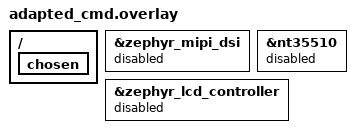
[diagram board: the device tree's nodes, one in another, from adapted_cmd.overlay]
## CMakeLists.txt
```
# SPDX-License-Identifier: MIT
# Zephyr application for STM32H747I-DISCO rlvgl demo.
#
# Build:
#   west build -b stm32h747i_disco/stm32h747xx/m7 \
#       examples/stm32h747i-disco/zephyr \
#       -- -DSHIELD=st_b_lcd40_dsi1_mb1166_a09
#
# The Rust static library is built separately and linked via
# target_link_libraries. See README for the two-step build flow.

cmake_minimum_required(VERSION 3.20.0)
find_package(Zephyr REQUIRED HINTS $ENV{ZEPHYR_BASE})
project(rlvgl_disco_zephyr C)

target_sources(app PRIVATE src/main.c)

# Link the Rust static library built by cargo.
# The library path assumes cargo was invoked from the workspace root:
#   RUSTFLAGS="-C target-cpu=cortex-m7" cargo build \
#       --target thumbv7em-none-eabihf \
#       -p rlvgl-example-disco \
#       --features cm7,dma2d,splash,desktop,zephyr \
#       --lib
#
# Adjust the path if your build layout differs.
set(RLVGL_RUST_LIB
    ${CMAKE_CURRENT_SOURCE_DIR}/../../../target/thumbv7em-none-eabihf/debug/librlvgl_example_disco.a)

if(EXISTS ${RLVGL_RUST_LIB})
    target_link_libraries(app PUBLIC ${RLVGL_RUST_LIB})
else()
    message(WARNING "Rust library not found at ${RLVGL_RUST_LIB} — build the Rust side first.")
endif()
```

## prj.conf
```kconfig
# rlvgl STM32H747I-DISCO Zephyr demo
# Kernel
# 16 KiB main stack: render loop hosts the controller widget tree, the
# StarCrawl struct (~800 B scanline buffer), `RotatedRenderer`, and
# per-pixel `BlitterRenderer.draw_pixels` recursion. Default 4 KiB
# overflowed during crawl render and reset the board.
CONFIG_MAIN_STACK_SIZE=16384
CONFIG_FPU=y
CONFIG_SYSTEM_WORKQUEUE_STACK_SIZE=2048
CONFIG_HEAP_MEM_POOL_SIZE=65536

# Display subsystem
CONFIG_DISPLAY=y
CONFIG_STM32_LTDC_FB_NUM=2

# MIPI-DSI — Zephyr video-mode driver for initial bringup
CONFIG_MIPI_DSI=y

# I2C for FT5336 touch
CONFIG_I2C=y
CONFIG_INPUT=y
CONFIG_INPUT_FT5336=y
CONFIG_INPUT_FT5336_INTERRUPT=n
CONFIG_INPUT_FT5336_PERIOD=10

# Synchronous mode: input_report dispatches to callbacks inline,
# no msgq / thread. Avoids "queue full, event dropped" when main
# thread's render loop starves the input dispatch thread.
CONFIG_INPUT_MODE_SYNCHRONOUS=y

# SDRAM via FMC
CONFIG_MEMC=y
CONFIG_MEMC_STM32=y

# DMA2D (no Zephyr driver — raw register access from Rust)
# Enable the clock gate via DT overlay.

# Serial console
CONFIG_SERIAL=y
CONFIG_UART_INTERRUPT_DRIVEN=y
CONFIG_CONSOLE=y
CONFIG_UART_CONSOLE=y

# Logging — DBG on INPUT so FT5336 polling path prints its per-touch lines.
CONFIG_LOG=y
CONFIG_LOG_MODE_IMMEDIATE=y
CONFIG_LOG_DEFAULT_LEVEL=3
CONFIG_INPUT_LOG_LEVEL_DBG=y

# SD card via SDMMC
CONFIG_DISK_ACCESS=y
CONFIG_SDMMC_STM32=y

# QSPI flash
CONFIG_FLASH=y
CONFIG_FLASH_STM32_QSPI=y

# Filesystem: FatFS with multi-volume support
CONFIG_FILE_SYSTEM=y
CONFIG_FAT_FILESYSTEM_ELM=y
CONFIG_FS_FATFS_MAX_SS=512
CONFIG_FS_FATFS_LFN=y

# GPIO for scope probes, backlight, and joystick
CONFIG_GPIO=y
CONFIG_INPUT_GPIO_KEYS=y

# Interrupts
CONFIG_DYNAMIC_INTERRUPTS=y
```

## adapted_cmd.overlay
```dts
/*
 * Adapted command mode overlay — disables Zephyr's DSI/LTDC/NT35510
 * driver init so the Rust code can do full DSI+LTDC init from scratch
 * in adapted command mode.
 *
 * Apply via west: -DEXTRA_DTC_OVERLAY_FILE=adapted_cmd.overlay
 *
 * Zephyr keeps providing: SDRAM (memc), clocks (PLL3), GPIO, I2C,
 *   joystick (gpio_keys), kernel, filesystem, console.
 */

&zephyr_mipi_dsi {
	status = "disabled";
};

&nt35510 {
	status = "disabled";
};

&zephyr_lcd_controller {
	status = "disabled";
};

/ {
	chosen {
		/delete-property/ zephyr,display;
	};
};
```

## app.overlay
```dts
/*
 * Device tree overlay for rlvgl Zephyr demo on STM32H747I-DISCO.
 *
 * Uses the st_b_lcd40_dsi1_mb1166_a09 shield for NT35510 panel/touch
 * setup. This overlay disables the Zephyr DSI driver (video-mode only)
 * so that the Rust code can perform raw register adapted-command-mode
 * init instead.
 *
 * LTDC remains enabled — Zephyr's LTDC driver handles framebuffer in
 * SDRAM and the display API surface.
 */

/* Phase 5 bringup: let Zephyr's DSI driver init in video mode. */

/* Enable joystick buttons for navigation. */
&joy_center { status = "okay"; };
&joy_down   { status = "okay"; };
&joy_up     { status = "okay"; };
&joy_left   { status = "okay"; };
&joy_right  { status = "okay"; };
```

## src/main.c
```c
/*
 * SPDX-License-Identifier: MIT
 *
 * Zephyr C application shell for the rlvgl STM32H747I-DISCO demo.
 *
 * Defines kernel objects (semaphores, thread stacks) and ISR wrappers,
 * then calls into the Rust static library via rlvgl_init().
 */

#include <zephyr/kernel.h>
#include <zephyr/device.h>
#include <zephyr/irq.h>
#include <zephyr/drivers/display.h>
#include <zephyr/drivers/i2c.h>
#include <zephyr/drivers/gpio.h>
#include <zephyr/drivers/uart.h>
#include <zephyr/cache.h>
#include <zephyr/input/input.h>
#include <string.h>
#include <zephyr/fs/fs.h>
#include <ff.h>

/* ── Early PG3 reset pulse ──────────────────────────────────────────────
 *
 * On ACM builds the zephyr `nt35510` node is disabled by overlay, so
 * Zephyr never pulses the shared DSI/touch reset line (PG3). Meanwhile,
 * the FT5336 driver init runs at POST_KERNEL 50 and starts hammering the
 * chip with I2C reads immediately. The FT5336 IC apparently enters a
 * broken state when it receives I2C before its first reset — subsequent
 * resets recover it to "ACK but all-zero registers" rather than normal
 * operation.
 *
 * Fix: drop in a pre-POST_KERNEL SYS_INIT hook that pulses PG3 BEFORE
 * the FT5336 driver comes up, mimicking what Zephyr's NT35510 driver
 * would have done on a non-ACM build. Priority 45 runs ahead of the
 * default input-device priority of 50.
 */
static int ft5336_early_reset(void)
{
	const struct device *gpiog = DEVICE_DT_GET(DT_NODELABEL(gpiog));
	if (!device_is_ready(gpiog)) {
		return -ENODEV;
	}
	gpio_pin_configure(gpiog, 3, GPIO_OUTPUT_ACTIVE);
	gpio_pin_set(gpiog, 3, 0); /* low = hold in reset */
	k_busy_wait(10000);        /* 10 ms */
	gpio_pin_set(gpiog, 3, 1); /* high = release reset */
	k_busy_wait(300000);       /* 300 ms settle for chip boot */
	return 0;
}
SYS_INIT(ft5336_early_reset, POST_KERNEL, 45);

/* ── Kernel objects ──────────────────────────────────────────────────── */

K_SEM_DEFINE(erif_sem, 0, 1);
K_SEM_DEFINE(dma2d_done_sem, 0, 1);

/* ── Display info passed to Rust ─────────────────────────────────────── */

struct rlvgl_display_info {
	uint8_t *fb_front;       /* front framebuffer (currently displayed) */
	uint8_t *fb_back;        /* back framebuffer (render target) */
	uint32_t fb_len;         /* bytes per framebuffer */
	uint16_t width;          /* portrait width (480) */
	uint16_t height;         /* portrait height (800) */
	uint16_t pixel_size;     /* bytes per pixel (4 for ARGB8888) */
};

/* ── Rust FFI declarations ───────────────────────────────────────────── */

extern void rlvgl_init(struct k_sem *erif_sem,
		       struct k_sem *dma2d_done_sem,
		       const struct rlvgl_display_info *display_info);
extern void rlvgl_dsi_isr(void);
extern void rlvgl_dma2d_isr(void);

/* ── FFI wrappers for Zephyr kernel API ─────────────────────────────── */

int rlvgl_k_sem_take(struct k_sem *sem, k_timeout_t timeout)
{
	return k_sem_take(sem, timeout);
}

void rlvgl_k_sem_give(struct k_sem *sem)
{
	k_sem_give(sem);
}

/* D-cache clean — flush all dirty lines to SDRAM. */
void rlvgl_dcache_clean(void)
{
	SCB_CleanDCache();
}

/* Sleep wrapper for Rust render loop frame pacing. */
void rlvgl_k_sleep_ms(uint32_t ms)
{
	k_sleep(K_MSEC(ms));
}

/* ── USART1 RX poll for test automation ──────────────────────────────
 *
 * Polls the Zephyr UART device for a single byte using uart_poll_in().
 * Non-blocking: returns -1 if no byte available, otherwise the byte
 * value in the low 8 bits. Lets Rust inject debug-trigger characters
 * (e.g. 'c' to fire the star crawl) from a serial terminal without
 * needing touch/joystick input.
 *
 * Uses the device chosen as zephyr,console (USART1 per stm32h747i_disco
 * overlay). Both Zephyr console TX (printk) and our raw TX writes
 * coexist with the poll-based RX since RX is a separate FIFO. */
int32_t rlvgl_serial_poll_rx(void)
{
	const struct device *uart_dev = DEVICE_DT_GET(DT_CHOSEN(zephyr_console));
	if (!device_is_ready(uart_dev)) {
		return -1;
	}
	unsigned char c;
	int r = uart_poll_in(uart_dev, &c);
	if (r == 0) {
		return (int32_t)c;
	}
	return -1;
}

/* Present: trigger Zephyr LTDC driver's double-buffer swap.
 * Writes the full back buffer as a new frame, which triggers
 * LINE ISR -> CFBAR update -> sem give. Blocks until swap completes.
 *
 * When Zephyr display is disabled (adapted_cmd path), Rust calls
 * `dsi_cmd_mode::present()` directly instead of this function. */
#if DT_HAS_CHOSEN(zephyr_display)
static const struct device *g_disp;

int rlvgl_present(const uint8_t *back_buf, uint16_t width, uint16_t height)
{
	if (!g_disp) return -1;
	struct display_buffer_descriptor desc = {
		.buf_size = width * height * 4, /* ARGB8888 */
		.width = width,
		.height = height,
		.pitch = width,
	};
	return display_write(g_disp, 0, 0, &desc, back_buf);
}
#else
int rlvgl_present(const uint8_t *back_buf, uint16_t width, uint16_t height)
{
	(void)back_buf; (void)width; (void)height;
	return -1; /* Rust uses dsi_cmd_mode::present() directly */
}
#endif

/* ── Touch input ─────────────────────────────────────────────────────── */

/* Raw USART1 banner — bypasses Zephyr console driver so we can tell
 * whether main() is running at all, independent of console routing. */
static void usart1_raw_str(const char *s)
{
	volatile uint32_t *isr = (volatile uint32_t *)0x4001101C;
	volatile uint32_t *tdr = (volatile uint32_t *)0x40011028;
	while (*s) {
		uint32_t t = 100000;
		while (!(*isr & (1 << 7))) { if (--t == 0) break; }
		*tdr = (uint32_t)(uint8_t)*s;
		s++;
	}
}

/* Touch event sent to Rust. Coordinates are raw panel space. */
struct rlvgl_touch_event {
	int16_t x;
	int16_t y;
	uint8_t pressed; /* 1=down/move, 0=up */
};

/* Rust FFI: queue a touch or key event. */
extern void rlvgl_touch_event(const struct rlvgl_touch_event *evt);
extern void rlvgl_key_event(uint16_t code, uint8_t pressed);

static int16_t touch_x, touch_y;
static bool touch_pressed;

static void input_cb(struct input_event *evt, void *user_data)
{
	ARG_UNUSED(user_data);

	/* Debug: mark every input event with 'I' on USART1 so we can tell
	 * whether Zephyr's input subsystem delivers events from FT5336 /
	 * gpio_keys at all. */
	usart1_raw_str("I");

	switch (evt->code) {
	case INPUT_ABS_X:
		touch_x = (int16_t)evt->value;
		break;
	case INPUT_ABS_Y:
		touch_y = (int16_t)evt->value;
		break;
	case INPUT_BTN_TOUCH:
		touch_pressed = evt->value != 0;
		break;
	/* Joystick / GPIO keys: forward immediately */
	case INPUT_KEY_ENTER:
	case INPUT_KEY_UP:
	case INPUT_KEY_DOWN:
	case INPUT_KEY_LEFT:
	case INPUT_KEY_RIGHT:
		rlvgl_key_event(evt->code, evt->value ? 1 : 0);
		return;
	}

	if (evt->sync) {
		struct rlvgl_touch_event te = {
			.x = touch_x,
			.y = touch_y,
			.pressed = touch_pressed ? 1 : 0,
		};
		rlvgl_touch_event(&te);
	}
}
INPUT_CALLBACK_DEFINE(NULL, input_cb, NULL);

/* ── Filesystem helpers for Rust FFI ──────────────────────────────────── */

/* Directory entry passed to Rust callback. */
struct rlvgl_dirent {
	char name[256];
	uint8_t is_dir; /* 1 = directory, 0 = file */
	uint32_t size;
};

/* List directory contents. Calls `cb` for each entry. Returns 0 on
 * success, negative errno on failure. */
int rlvgl_readdir(const char *path,
		  void (*cb)(const struct rlvgl_dirent *entry, void *ctx),
		  void *ctx)
{
	struct fs_dir_t dir;
	struct fs_dirent ent;
	int ret;

	fs_dir_t_init(&dir);
	ret = fs_opendir(&dir, path);
	if (ret < 0) {
		return ret;
	}

	while (1) {
		ret = fs_readdir(&dir, &ent);
		if (ret < 0 || ent.name[0] == 0) {
			break;
		}
		struct rlvgl_dirent re;
		/* Copy name, ensure NUL termination */
		strncpy(re.name, ent.name, sizeof(re.name) - 1);
		re.name[sizeof(re.name) - 1] = '\0';
		re.is_dir = (ent.type == FS_DIR_ENTRY_DIR) ? 1 : 0;
		re.size = (uint32_t)ent.size;
		cb(&re, ctx);
	}

	fs_closedir(&dir);
	return 0;
}

/* ── ISR wrappers ────────────────────────────────────────────────────── */

static void dsi_isr_wrapper(const void *arg)
{
	ARG_UNUSED(arg);
	rlvgl_dsi_isr();
}

static void dma2d_isr_wrapper(const void *arg)
{
	ARG_UNUSED(arg);
	rlvgl_dma2d_isr();
}

/* ── Main ────────────────────────────────────────────────────────────── */

int main(void)
{
	/* SRAM3 breadcrumbs: probe-rs can read these without the board
	 * being able to print to UART. Lets us tell whether main()
	 * runs at all when serial is silent. */
	*(volatile uint32_t *)0x38000200 = 0xB0070001; /* main entered */
	usart1_raw_str("\r\n[C-MAIN]\r\n");
	printk("rlvgl-zephyr: starting\n");
	usart1_raw_str("[C-after-printk]\r\n");
	*(volatile uint32_t *)0x38000200 = 0xB0070002; /* after first printk */

	/* Probe FT5336 device readiness — helps tell whether the i2c touch
	 * controller actually bound in this build (adapted_cmd overlay
	 * disables zephyr display nodes, which may have collaterally removed
	 * parents the FT5336 node depended on).
	 *
	 * Also: pulse PG3 (the shared DSI/touch reset line) from here so the
	 * FT5336 IC gets a clean reset BEFORE the Rust panel init runs —
	 * matches what Zephyr's normal NT35510 driver would have done at
	 * POST_KERNEL 87, and unblocks the FT5336 polling which was
	 * starting in an indeterminate state on the ACM build. Then probe
	 * the chip ID over I2C to verify it responds with real data (not
	 * just 0s) after reset. */
#if DT_NODE_EXISTS(DT_NODELABEL(ft5336))
	{
		const struct device *ft5336_dev =
			DEVICE_DT_GET(DT_NODELABEL(ft5336));
		if (ft5336_dev == NULL) {
			printk("rlvgl-zephyr: ft5336 DEVICE_DT_GET returned NULL\n");
		} else if (!device_is_ready(ft5336_dev)) {
			printk("rlvgl-zephyr: ft5336 NOT READY\n");
		} else {
			printk("rlvgl-zephyr: ft5336 OK, name=%s\n",
			       ft5336_dev->name);

			/* Verify FT5336 is in good state after the early
			 * SYS_INIT reset (ft5336_early_reset at POST_KERNEL 45).
			 * Chip ID 0x64 indicates a healthy FT5x36 family chip.
			 * NO second reset here — doing so corrupts the chip.
			 *
			 * Also force REG_CTRL (0x86) = 0x00 ("keep active" mode).
			 * Default is 0x01 (monitor mode) where the chip only
			 * scans the sensor after activity on the INT pin — that
			 * keeps TD_STATUS stuck at 0 under Zephyr's polling-only
			 * driver on our PG3-shared-reset build. */
			const struct device *i2c_dev =
				DEVICE_DT_GET(DT_BUS(DT_NODELABEL(ft5336)));
			if (device_is_ready(i2c_dev)) {
				uint8_t chip_id = 0xFF, fw_ver = 0xFF, ctrl = 0xFF;
				int r1 = i2c_reg_read_byte(i2c_dev, 0x38, 0xA3, &chip_id);
				int r2 = i2c_reg_read_byte(i2c_dev, 0x38, 0xA6, &fw_ver);
				int r3 = i2c_reg_read_byte(i2c_dev, 0x38, 0x86, &ctrl);
				printk("rlvgl-zephyr: ft5336 chip_id=0x%02x rc=%d, "
				       "fw=0x%02x rc=%d, ctrl=0x%02x rc=%d\n",
				       chip_id, r1, fw_ver, r2, ctrl, r3);
				int r4 = i2c_reg_write_byte(i2c_dev, 0x38, 0x86, 0x00);
				uint8_t ctrl_rb = 0xFF;
				int r5 = i2c_reg_read_byte(i2c_dev, 0x38, 0x86, &ctrl_rb);
				printk("rlvgl-zephyr: ft5336 WR CTRL=0 rc=%d, RB=0x%02x rc=%d\n",
				       r4, ctrl_rb, r5);
			}
		}
	}
#else
	printk("rlvgl-zephyr: ft5336 DT node MISSING\n");
#endif

	/* Register DMA2D ISR (IRQ 90, pri 3). */
	irq_connect_dynamic(90, 3, dma2d_isr_wrapper, NULL, 0);
	irq_enable(90);

	/* Register DSI ISR (IRQ 123, pri 2).
	 * In video mode this is a no-op (ERIF never fires).
	 * In adapted command mode (Rust feature "adapted_cmd"), the ERIF
	 * handler clears LTDCEN after each scan, giving DMA2D exclusive
	 * SDRAM access for the render window. */
	irq_connect_dynamic(123, 2, dsi_isr_wrapper, NULL, 0);
	irq_enable(123);

	uint8_t *fb_front;
	uint8_t *fb_back;
	uint16_t fb_w;
	uint16_t fb_h;
	uint16_t px_sz = 4; /* ARGB8888 */
	uint32_t fb_len;

#if DT_HAS_CHOSEN(zephyr_display)
	/* ── Display bringup via Zephyr display API (video mode) ────── */
	g_disp = DEVICE_DT_GET(DT_CHOSEN(zephyr_display));
	if (!device_is_ready(g_disp)) {
		printk("rlvgl-zephyr: display not ready!\n");
		return -1;
	}

	struct display_capabilities caps;
	display_get_capabilities(g_disp, &caps);
	printk("rlvgl-zephyr: display %ux%u fmt=%u\n",
	       caps.x_resolution, caps.y_resolution,
	       caps.current_pixel_format);

	display_blanking_off(g_disp);
	printk("rlvgl-zephyr: blanking off\n");

	/* In video mode with rotation=90, the LTDC scans landscape:
	 * 800 pixels per line, 480 lines. */
	fb_front = (uint8_t *)display_get_framebuffer(g_disp);
	fb_w = caps.x_resolution; /* 800 */
	fb_h = caps.y_resolution; /* 480 */
	fb_len = fb_w * fb_h * px_sz;
	fb_back = fb_front + fb_len;
#else
	/* ── Adapted command mode: hardcoded FB addresses ──────────── */
	/* SDRAM Bank 0 = 0xD000_0000, Bank 1 = 0xD080_0000 (matches
	 * bare-metal). NT35510 native portrait 480x800. */
	fb_front = (uint8_t *)0xD0000000;
	fb_back  = (uint8_t *)0xD0800000;
	fb_w = 480;
	fb_h = 800;
	fb_len = fb_w * fb_h * px_sz;
	printk("rlvgl-zephyr: adapted_cmd mode (full Rust DSI init)\n");
#endif

	printk("rlvgl-zephyr: fb_front=%p fb_back=%p fb_len=%u\n",
	       fb_front, fb_back, fb_len);

	struct rlvgl_display_info di = {
		.fb_front = fb_front,
		.fb_back = fb_back,
		.fb_len = fb_len,
		.width = fb_w,
		.height = fb_h,
		.pixel_size = px_sz,
	};

	/* ── Filesystem: mount SD card ────────────────────────────── */
	static FATFS sd_fatfs;
	static struct fs_mount_t sd_mnt = {
		.type = FS_FATFS,
		.fs_data = &sd_fatfs,
		.mnt_point = "/SD:",
	};
	int fs_ret = fs_mount(&sd_mnt);
	if (fs_ret == 0) {
		printk("rlvgl-zephyr: SD mounted at /SD:\n");
	} else {
		printk("rlvgl-zephyr: SD mount failed (%d)\n", fs_ret);
	}

	*(volatile uint32_t *)0x38000200 = 0xB0070010; /* about to call rlvgl_init */
	printk("rlvgl-zephyr: calling rlvgl_init\n");
	rlvgl_init(&erif_sem, &dma2d_done_sem, &di);
	*(volatile uint32_t *)0x38000200 = 0xB0070011; /* rlvgl_init returned */
	printk("rlvgl-zephyr: init complete\n");

	/* Keep main thread alive. */
	while (1) {
		k_sleep(K_SECONDS(5));
		printk("rlvgl-zephyr: heartbeat\n");
	}

	return 0;
}
```
